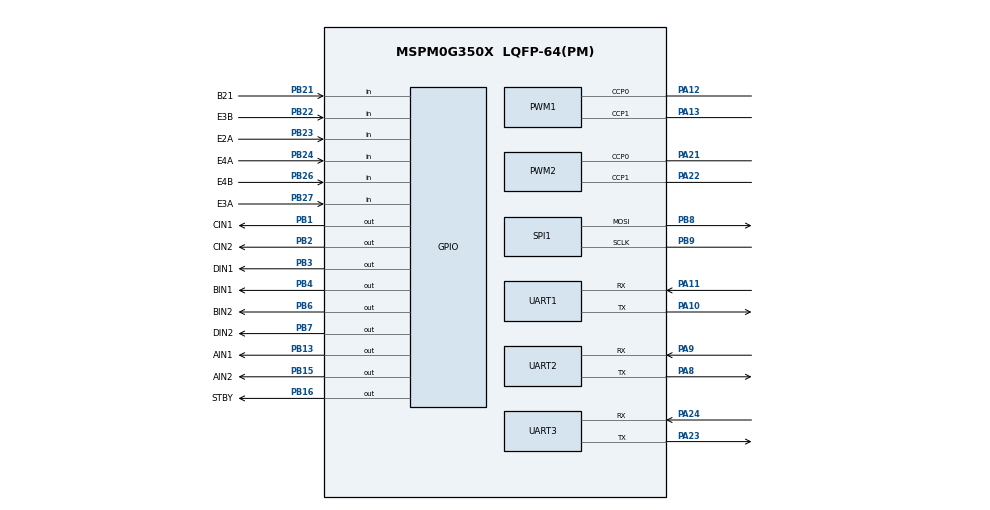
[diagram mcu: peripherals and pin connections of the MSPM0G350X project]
/**
 * @cliArgs --device "MSPM0G350X" --part "Default" --package "LQFP-64(PM)" --product "mspm0_sdk@2.05.01.00"
 * @versions {"tool":"1.24.1+4189"}
 */

/**
 * Import the modules used in this configuration.
 */
const GPIO    = scripting.addModule("/ti/driverlib/GPIO", {}, false);
const GPIO1   = GPIO.addInstance();
const GPIO2   = GPIO.addInstance();
const GPIO3   = GPIO.addInstance();
const GPIO4   = GPIO.addInstance();
const GPIO5   = GPIO.addInstance();
const GPIO6   = GPIO.addInstance();
const GPIO7   = GPIO.addInstance();
const GPIO8   = GPIO.addInstance();
const PWM     = scripting.addModule("/ti/driverlib/PWM", {}, false);
const PWM1    = PWM.addInstance();
const PWM2    = PWM.addInstance();
const SPI     = scripting.addModule("/ti/driverlib/SPI", {}, false);
const SPI1    = SPI.addInstance();
const SYSCTL  = scripting.addModule("/ti/driverlib/SYSCTL");
const SYSTICK = scripting.addModule("/ti/driverlib/SYSTICK");
const UART    = scripting.addModule("/ti/driverlib/UART", {}, false);
const UART1   = UART.addInstance();
const UART2   = UART.addInstance();
const UART3   = UART.addInstance();

/**
 * Write custom configuration values to the imported modules.
 */
const divider7       = system.clockTree["PLL_PDIV"];
divider7.divideValue = 2;

const divider9       = system.clockTree["UDIV"];
divider9.divideValue = 2;

const multiplier2         = system.clockTree["PLL_QDIV"];
multiplier2.multiplyValue = 5;

const mux8       = system.clockTree["HSCLKMUX"];
mux8.inputSelect = "HSCLKMUX_SYSPLL2X";

GPIO1.$name                          = "SPI_OLED_CTRL";
GPIO1.port                           = "PORTB";
GPIO1.associatedPins.create(3);
GPIO1.associatedPins[0].initialValue = "SET";
GPIO1.associatedPins[0].assignedPin  = "14";
GPIO1.associatedPins[0].$name        = "CS";
GPIO1.associatedPins[1].initialValue = "SET";
GPIO1.associatedPins[1].assignedPin  = "11";
GPIO1.associatedPins[1].$name        = "DC";
GPIO1.associatedPins[2].initialValue = "SET";
GPIO1.associatedPins[2].assignedPin  = "10";
GPIO1.associatedPins[2].$name        = "RES";

const Board = scripting.addModule("/ti/driverlib/Board", {}, false);

GPIO2.$name                              = "GPIO_GRAY";
GPIO2.associatedPins.create(8);
GPIO2.associatedPins[0].$name            = "PIN_0";
GPIO2.associatedPins[0].direction        = "INPUT";
GPIO2.associatedPins[0].assignedPort     = "PORTB";
GPIO2.associatedPins[0].assignedPin      = "19";
GPIO2.associatedPins[0].internalResistor = "PULL_UP";
GPIO2.associatedPins[1].$name            = "PIN_1";
GPIO2.associatedPins[1].direction        = "INPUT";
GPIO2.associatedPins[1].assignedPort     = "PORTB";
GPIO2.associatedPins[1].assignedPin      = "17";
GPIO2.associatedPins[1].internalResistor = "PULL_UP";
GPIO2.associatedPins[2].$name            = "PIN_2";
GPIO2.associatedPins[2].direction        = "INPUT";
GPIO2.associatedPins[2].assignedPort     = "PORTA";
GPIO2.associatedPins[2].assignedPin      = "16";
GPIO2.associatedPins[2].internalResistor = "PULL_UP";
GPIO2.associatedPins[3].$name            = "PIN_3";
GPIO2.associatedPins[3].direction        = "INPUT";
GPIO2.associatedPins[3].assignedPort     = "PORTA";
GPIO2.associatedPins[3].assignedPin      = "14";
GPIO2.associatedPins[3].internalResistor = "PULL_UP";
GPIO2.associatedPins[4].$name            = "PIN_4";
GPIO2.associatedPins[4].direction        = "INPUT";
GPIO2.associatedPins[4].assignedPort     = "PORTB";
GPIO2.associatedPins[4].assignedPin      = "20";
GPIO2.associatedPins[4].internalResistor = "PULL_UP";
GPIO2.associatedPins[5].$name            = "PIN_5";
GPIO2.associatedPins[5].direction        = "INPUT";
GPIO2.associatedPins[5].assignedPort     = "PORTB";
GPIO2.associatedPins[5].assignedPin      = "25";
GPIO2.associatedPins[5].internalResistor = "PULL_UP";
GPIO2.associatedPins[6].$name            = "PIN_6";
GPIO2.associatedPins[6].direction        = "INPUT";
GPIO2.associatedPins[6].assignedPort     = "PORTA";
GPIO2.associatedPins[6].assignedPin      = "25";
GPIO2.associatedPins[6].internalResistor = "PULL_UP";
GPIO2.associatedPins[7].$name            = "PIN_7";
GPIO2.associatedPins[7].direction        = "INPUT";
GPIO2.associatedPins[7].assignedPort     = "PORTA";
GPIO2.associatedPins[7].assignedPin      = "27";
GPIO2.associatedPins[7].internalResistor = "PULL_UP";

GPIO3.$name                          = "GPIO_MOTOR";
GPIO3.associatedPins.create(9);
GPIO3.associatedPins[0].$name        = "AIN1";
GPIO3.associatedPins[0].assignedPort = "PORTB";
GPIO3.associatedPins[0].pin.$assign  = "PB13";
GPIO3.associatedPins[1].$name        = "AIN2";
GPIO3.associatedPins[1].pin.$assign  = "PB15";
GPIO3.associatedPins[2].$name        = "STBY";
GPIO3.associatedPins[2].initialValue = "CLEARED";
GPIO3.associatedPins[2].pin.$assign  = "PB16";
GPIO3.associatedPins[3].$name        = "BIN1";
GPIO3.associatedPins[3].assignedPort = "PORTB";
GPIO3.associatedPins[3].pin.$assign  = "PB4";
GPIO3.associatedPins[4].$name        = "BIN2";
GPIO3.associatedPins[4].pin.$assign  = "PB6";
GPIO3.associatedPins[5].$name        = "CIN1";
GPIO3.associatedPins[5].assignedPort = "PORTB";
GPIO3.associatedPins[5].pin.$assign  = "PB1";
GPIO3.associatedPins[6].$name        = "CIN2";
GPIO3.associatedPins[6].pin.$assign  = "PB2";
GPIO3.associatedPins[7].$name        = "DIN1";
GPIO3.associatedPins[7].pin.$assign  = "PB3";
GPIO3.associatedPins[8].$name        = "DIN2";
GPIO3.associatedPins[8].pin.$assign  = "PB7";

GPIO4.$name                              = "GPIO_ENCODERA";
GPIO4.port                               = "PORTB";
GPIO4.associatedPins.create(2);
GPIO4.associatedPins[0].$name            = "E1A";
GPIO4.associatedPins[0].direction        = "INPUT";
GPIO4.associatedPins[0].internalResistor = "PULL_UP";
GPIO4.associatedPins[0].interruptEn      = true;
GPIO4.associatedPins[0].polarity         = "RISE_FALL";
GPIO4.associatedPins[0].assignedPin      = "0";
GPIO4.associatedPins[1].$name            = "E1B";
GPIO4.associatedPins[1].direction        = "INPUT";
GPIO4.associatedPins[1].internalResistor = "PULL_UP";
GPIO4.associatedPins[1].interruptEn      = true;
GPIO4.associatedPins[1].polarity         = "RISE_FALL";
GPIO4.associatedPins[1].assignedPin      = "5";

GPIO5.$name                              = "GPIO_ENCODERB";
GPIO5.port                               = "PORTB";
GPIO5.associatedPins.create(2);
GPIO5.associatedPins[0].$name            = "E2A";
GPIO5.associatedPins[0].direction        = "INPUT";
GPIO5.associatedPins[0].internalResistor = "PULL_UP";
GPIO5.associatedPins[0].interruptEn      = true;
GPIO5.associatedPins[0].polarity         = "RISE_FALL";
GPIO5.associatedPins[0].assignedPin      = "23";
GPIO5.associatedPins[0].pin.$assign      = "PB23";
GPIO5.associatedPins[1].$name            = "E2B";
GPIO5.associatedPins[1].direction        = "INPUT";
GPIO5.associatedPins[1].internalResistor = "PULL_UP";
GPIO5.associatedPins[1].interruptEn      = true;
GPIO5.associatedPins[1].polarity         = "RISE_FALL";
GPIO5.associatedPins[1].assignedPin      = "18";

GPIO6.$name                              = "GPIO_ENCODERC";
GPIO6.port                               = "PORTB";
GPIO6.associatedPins.create(2);
GPIO6.associatedPins[0].$name            = "E3A";
GPIO6.associatedPins[0].direction        = "INPUT";
GPIO6.associatedPins[0].internalResistor = "PULL_UP";
GPIO6.associatedPins[0].interruptEn      = true;
GPIO6.associatedPins[0].polarity         = "RISE_FALL";
GPIO6.associatedPins[0].assignedPin      = "27";
GPIO6.associatedPins[0].pin.$assign      = "PB27";
GPIO6.associatedPins[1].$name            = "E3B";
GPIO6.associatedPins[1].direction        = "INPUT";
GPIO6.associatedPins[1].internalResistor = "PULL_UP";
GPIO6.associatedPins[1].interruptEn      = true;
GPIO6.associatedPins[1].polarity         = "RISE_FALL";
GPIO6.associatedPins[1].assignedPin      = "22";
GPIO6.associatedPins[1].pin.$assign      = "PB22";

GPIO7.$name                              = "GPIO_ENCODERD";
GPIO7.port                               = "PORTB";
GPIO7.associatedPins.create(2);
GPIO7.associatedPins[0].$name            = "E4A";
GPIO7.associatedPins[0].direction        = "INPUT";
GPIO7.associatedPins[0].internalResistor = "PULL_UP";
GPIO7.associatedPins[0].interruptEn      = true;
GPIO7.associatedPins[0].polarity         = "RISE_FALL";
GPIO7.associatedPins[0].assignedPin      = "24";
GPIO7.associatedPins[0].pin.$assign      = "PB24";
GPIO7.associatedPins[1].$name            = "E4B";
GPIO7.associatedPins[1].direction        = "INPUT";
GPIO7.associatedPins[1].internalResistor = "PULL_UP";
GPIO7.associatedPins[1].interruptEn      = true;
GPIO7.associatedPins[1].polarity         = "RISE_FALL";
GPIO7.associatedPins[1].assignedPin      = "26";
GPIO7.associatedPins[1].pin.$assign      = "PB26";

/*
 * 板载用户键 B21 = PB21（按下接 GND，需上拉；未按=高，按下=低）
 * 与 OLED SPI MISO 冲突：SPI 仅写屏用 direction=PICO，释放 PB21。
 */
GPIO8.$name                              = "GPIO_KEY";
GPIO8.port                               = "PORTB";
GPIO8.associatedPins.create(1);
GPIO8.associatedPins[0].$name            = "B21";
GPIO8.associatedPins[0].direction        = "INPUT";
GPIO8.associatedPins[0].internalResistor = "PULL_UP";
GPIO8.associatedPins[0].assignedPin      = "21";
GPIO8.associatedPins[0].pin.$assign      = "PB21";

/*
 * Motor PWM — real board (LCKFB-TMX):
 *   PWMA MotorA  PA12  TIMG0_CCP0
 *   PWMC MotorC  PA13  TIMG0_CCP1   (same timer, dual channel)
 *   PWMB MotorB  PA21  TIMG6_CCP0
 *   PWMD MotorD  PA22  TIMG6_CCP1   (same timer, dual channel)
 *
 * Note: PA13 has no non-CMPL TIMA0 CCP3; TIMG0_CCP1 is the SysConfig-friendly
 * pinmux that matches the soldered net PWMC=PA13 without duty inversion.
 */
PWM1.$name                              = "PWMA";
PWM1.timerStartTimer                    = true;
PWM1.ccIndex                            = [0, 1];
PWM1.timerCount                         = 4000;
PWM1.pwmMode                            = "EDGE_ALIGN_UP";
PWM1.PWM_CHANNEL_0.$name                = "ti_driverlib_pwm_PWMTimerCC0";
PWM1.PWM_CHANNEL_1.$name                = "ti_driverlib_pwm_PWMTimerCC1";
PWM1.ccp0PinConfig.$name                = "ti_driverlib_gpio_GPIOPinGeneric_pwma_c0";
PWM1.ccp0PinConfig.direction            = scripting.forceWrite("OUTPUT");
PWM1.ccp0PinConfig.hideOutputInversion  = scripting.forceWrite(false);
PWM1.ccp0PinConfig.onlyInternalResistor = scripting.forceWrite(false);
PWM1.ccp0PinConfig.passedPeripheralType = scripting.forceWrite("Digital");
PWM1.ccp1PinConfig.$name                = "ti_driverlib_gpio_GPIOPinGeneric_pwma_c1";
PWM1.ccp1PinConfig.direction            = scripting.forceWrite("OUTPUT");
PWM1.ccp1PinConfig.hideOutputInversion  = scripting.forceWrite(false);
PWM1.ccp1PinConfig.onlyInternalResistor = scripting.forceWrite(false);
PWM1.ccp1PinConfig.passedPeripheralType = scripting.forceWrite("Digital");
PWM1.peripheral.$assign                 = "TIMG0";
PWM1.peripheral.ccp0Pin.$assign         = "PA12";
PWM1.peripheral.ccp1Pin.$assign         = "PA13";

PWM2.$name                              = "PWMB";
PWM2.timerStartTimer                    = true;
PWM2.timerCount                         = 4000;
PWM2.clockPrescale                      = 2;
PWM2.pwmMode                            = "EDGE_ALIGN_UP";
PWM2.ccIndex                            = [0, 1];
PWM2.PWM_CHANNEL_0.$name                = "ti_driverlib_pwm_PWMTimerCC2";
PWM2.PWM_CHANNEL_1.$name                = "ti_driverlib_pwm_PWMTimerCC3";
PWM2.ccp0PinConfig.$name                = "ti_driverlib_gpio_GPIOPinGeneric_pwmb_c0";
PWM2.ccp0PinConfig.direction            = scripting.forceWrite("OUTPUT");
PWM2.ccp0PinConfig.hideOutputInversion  = scripting.forceWrite(false);
PWM2.ccp0PinConfig.onlyInternalResistor = scripting.forceWrite(false);
PWM2.ccp0PinConfig.passedPeripheralType = scripting.forceWrite("Digital");
PWM2.ccp1PinConfig.$name                = "ti_driverlib_gpio_GPIOPinGeneric_pwmb_c1";
PWM2.ccp1PinConfig.direction            = scripting.forceWrite("OUTPUT");
PWM2.ccp1PinConfig.hideOutputInversion  = scripting.forceWrite(false);
PWM2.ccp1PinConfig.onlyInternalResistor = scripting.forceWrite(false);
PWM2.ccp1PinConfig.passedPeripheralType = scripting.forceWrite("Digital");
PWM2.peripheral.$assign                 = "TIMG6";
PWM2.peripheral.ccp0Pin.$assign         = "PA21";
PWM2.peripheral.ccp1Pin.$assign         = "PA22";

SPI1.$name                              = "SPI_OLED";
SPI1.targetBitRate                      = 20000000;
SPI1.frameFormat                        = "MOTO3";
/* 仅主机发送：不占用 PB21(POCI)，留给板载 B21 按键 */
SPI1.direction                          = "PICO";
SPI1.sclkPinConfig.direction            = scripting.forceWrite("OUTPUT");
SPI1.sclkPinConfig.onlyInternalResistor = scripting.forceWrite(false);
SPI1.sclkPinConfig.passedPeripheralType = scripting.forceWrite("Digital");
SPI1.sclkPinConfig.$name                = "ti_driverlib_gpio_GPIOPinGeneric3";
SPI1.mosiPinConfig.direction            = scripting.forceWrite("OUTPUT");
SPI1.mosiPinConfig.hideOutputInversion  = scripting.forceWrite(false);
SPI1.mosiPinConfig.onlyInternalResistor = scripting.forceWrite(false);
SPI1.mosiPinConfig.passedPeripheralType = scripting.forceWrite("Digital");
SPI1.mosiPinConfig.$name                = "ti_driverlib_gpio_GPIOPinGeneric4";
SPI1.peripheral.$assign                 = "SPI1";
SPI1.peripheral.sclkPin.$assign         = "PB9";
SPI1.peripheral.mosiPin.$assign         = "PB8";

SYSCTL.forceDefaultClkConfig = true;
SYSCTL.clockTreeEn           = true;
scripting.suppress("For best practices when the CPUCLK is running at 32MHz and above, clear the flash status bit using DL_FlashCTL_executeClearStatus\\(\\) before executing any flash operation\\. Otherwise there may be false positives\\.", SYSCTL);

SYSTICK.periodEnable  = true;
SYSTICK.systickEnable = true;
SYSTICK.period        = 16777216;

/* DEBUG UART0: PA10 TX / PA11 RX @ 115200 */
UART1.$name                            = "DEBUG_UART";
UART1.targetBaudRate                   = 115200;
UART1.peripheral.$assign               = "UART0";
UART1.peripheral.rxPin.$assign         = "PA11";
UART1.peripheral.txPin.$assign         = "PA10";
UART1.txPinConfig.direction            = scripting.forceWrite("OUTPUT");
UART1.txPinConfig.hideOutputInversion  = scripting.forceWrite(false);
UART1.txPinConfig.onlyInternalResistor = scripting.forceWrite(false);
UART1.txPinConfig.passedPeripheralType = scripting.forceWrite("Digital");
UART1.txPinConfig.$name                = "ti_driverlib_gpio_GPIOPinGeneric_dbg_tx";
UART1.rxPinConfig.hideOutputInversion  = scripting.forceWrite(false);
UART1.rxPinConfig.onlyInternalResistor = scripting.forceWrite(false);
UART1.rxPinConfig.passedPeripheralType = scripting.forceWrite("Digital");
UART1.rxPinConfig.$name                = "ti_driverlib_gpio_GPIOPinGeneric_dbg_rx";

/*
 * TRANS UART1 (board nets TRANS_TX=PA9, TRANS_RX=PA8):
 * pinmux: PA8=UART1_TX, PA9=UART1_RX  → MCU TX on PA8, MCU RX on PA9.
 * Wire external module with TX↔RX cross relative to MCU pins.
 */
UART2.$name                            = "TRANS_UART";
UART2.targetBaudRate                   = 115200;
UART2.peripheral.$assign               = "UART1";
UART2.peripheral.txPin.$assign         = "PA8";
UART2.peripheral.rxPin.$assign         = "PA9";
UART2.txPinConfig.direction            = scripting.forceWrite("OUTPUT");
UART2.txPinConfig.hideOutputInversion  = scripting.forceWrite(false);
UART2.txPinConfig.onlyInternalResistor = scripting.forceWrite(false);
UART2.txPinConfig.passedPeripheralType = scripting.forceWrite("Digital");
UART2.txPinConfig.$name                = "ti_driverlib_gpio_GPIOPinGeneric_trans_tx";
UART2.rxPinConfig.hideOutputInversion  = scripting.forceWrite(false);
UART2.rxPinConfig.onlyInternalResistor = scripting.forceWrite(false);
UART2.rxPinConfig.passedPeripheralType = scripting.forceWrite("Digital");
UART2.rxPinConfig.$name                = "ti_driverlib_gpio_GPIOPinGeneric_trans_rx";

/* OUT2 UART2: PA23 TX / PA24 RX @ 115200 (e.g. MaixCAM) */
UART3.$name                            = "OUT2_UART";
UART3.targetBaudRate                   = 115200;
UART3.peripheral.$assign               = "UART2";
UART3.peripheral.txPin.$assign         = "PA23";
UART3.peripheral.rxPin.$assign         = "PA24";
UART3.txPinConfig.direction            = scripting.forceWrite("OUTPUT");
UART3.txPinConfig.hideOutputInversion  = scripting.forceWrite(false);
UART3.txPinConfig.onlyInternalResistor = scripting.forceWrite(false);
UART3.txPinConfig.passedPeripheralType = scripting.forceWrite("Digital");
UART3.txPinConfig.$name                = "ti_driverlib_gpio_GPIOPinGeneric_out2_tx";
UART3.rxPinConfig.hideOutputInversion  = scripting.forceWrite(false);
UART3.rxPinConfig.onlyInternalResistor = scripting.forceWrite(false);
UART3.rxPinConfig.passedPeripheralType = scripting.forceWrite("Digital");
UART3.rxPinConfig.$name                = "ti_driverlib_gpio_GPIOPinGeneric_out2_rx";

/**
 * Pinmux solution for unlocked pins/peripherals. This ensures that minor changes to the automatic solver in a future
 * version of the tool will not impact the pinmux you originally saw.  These lines can be completely deleted in order to
 * re-solve from scratch.
 */
GPIO1.associatedPins[0].pin.$suggestSolution = "PB14";
GPIO1.associatedPins[1].pin.$suggestSolution = "PB11";
GPIO1.associatedPins[2].pin.$suggestSolution = "PB10";
Board.peripheral.$suggestSolution            = "DEBUGSS";
Board.peripheral.swclkPin.$suggestSolution   = "PA20";
Board.peripheral.swdioPin.$suggestSolution   = "PA19";
GPIO2.associatedPins[0].pin.$suggestSolution = "PB19";
GPIO2.associatedPins[1].pin.$suggestSolution = "PB17";
GPIO2.associatedPins[2].pin.$suggestSolution = "PA16";
GPIO2.associatedPins[3].pin.$suggestSolution = "PA14";
GPIO2.associatedPins[4].pin.$suggestSolution = "PB20";
GPIO2.associatedPins[5].pin.$suggestSolution = "PB25";
GPIO2.associatedPins[6].pin.$suggestSolution = "PA25";
GPIO2.associatedPins[7].pin.$suggestSolution = "PA27";
GPIO4.associatedPins[0].pin.$suggestSolution = "PB0";
GPIO4.associatedPins[1].pin.$suggestSolution = "PB5";
GPIO5.associatedPins[1].pin.$suggestSolution = "PB18";
GPIO8.associatedPins[0].pin.$suggestSolution = "PB21";
